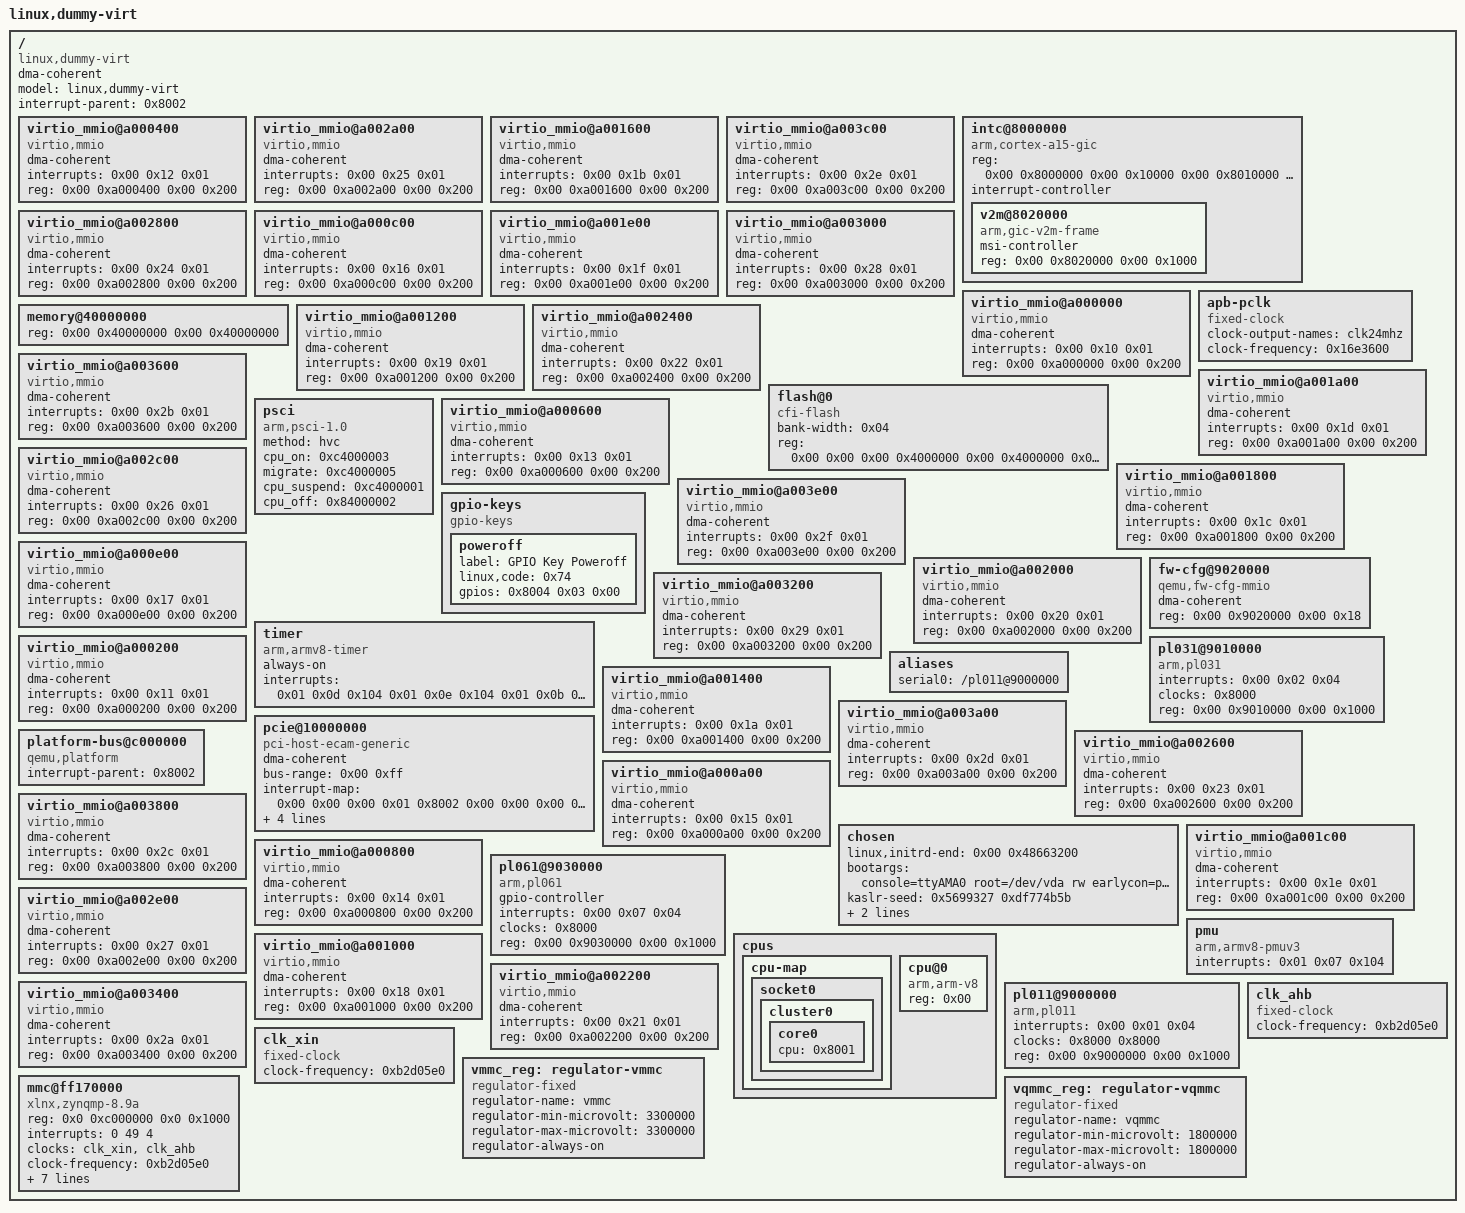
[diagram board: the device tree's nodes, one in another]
/dts-v1/;

/ {
	#address-cells = <0x02>;
	dma-coherent;
	model = "linux,dummy-virt";
	#size-cells = <0x02>;
	interrupt-parent = <0x8002>;
	compatible = "linux,dummy-virt";

	virtio_mmio@a000400 {
		dma-coherent;
		interrupts = <0x00 0x12 0x01>;
		compatible = "virtio,mmio";
		reg = <0x00 0xa000400 0x00 0x200>;
	};

	virtio_mmio@a002a00 {
		dma-coherent;
		interrupts = <0x00 0x25 0x01>;
		compatible = "virtio,mmio";
		reg = <0x00 0xa002a00 0x00 0x200>;
	};

	virtio_mmio@a001600 {
		dma-coherent;
		interrupts = <0x00 0x1b 0x01>;
		compatible = "virtio,mmio";
		reg = <0x00 0xa001600 0x00 0x200>;
	};

	virtio_mmio@a003c00 {
		dma-coherent;
		interrupts = <0x00 0x2e 0x01>;
		compatible = "virtio,mmio";
		reg = <0x00 0xa003c00 0x00 0x200>;
	};

	intc@8000000 {
		#address-cells = <0x02>;
		#size-cells = <0x02>;
		compatible = "arm,cortex-a15-gic";
		ranges;
		#interrupt-cells = <0x03>;
		reg = <0x00 0x8000000 0x00 0x10000 0x00 0x8010000 0x00 0x10000>;
		phandle = <0x8002>;
		interrupt-controller;

		v2m@8020000 {
			msi-controller;
			compatible = "arm,gic-v2m-frame";
			reg = <0x00 0x8020000 0x00 0x1000>;
			phandle = <0x8003>;
		};
	};

	virtio_mmio@a002800 {
		dma-coherent;
		interrupts = <0x00 0x24 0x01>;
		compatible = "virtio,mmio";
		reg = <0x00 0xa002800 0x00 0x200>;
	};

	virtio_mmio@a000c00 {
		dma-coherent;
		interrupts = <0x00 0x16 0x01>;
		compatible = "virtio,mmio";
		reg = <0x00 0xa000c00 0x00 0x200>;
	};

	virtio_mmio@a001e00 {
		dma-coherent;
		interrupts = <0x00 0x1f 0x01>;
		compatible = "virtio,mmio";
		reg = <0x00 0xa001e00 0x00 0x200>;
	};

	virtio_mmio@a003000 {
		dma-coherent;
		interrupts = <0x00 0x28 0x01>;
		compatible = "virtio,mmio";
		reg = <0x00 0xa003000 0x00 0x200>;
	};
	
	virtio_mmio@a000000 {
		dma-coherent;
		interrupts = <0x00 0x10 0x01>;
		compatible = "virtio,mmio";
		reg = <0x00 0xa000000 0x00 0x200>;
	};

	memory@40000000 {
		device_type = "memory";
		reg = <0x00 0x40000000 0x00 0x40000000>;
	};

	apb-pclk {
		clock-output-names = "clk24mhz";
		#clock-cells = <0x00>;
		clock-frequency = <0x16e3600>;
		compatible = "fixed-clock";
		phandle = <0x8000>;
	};

	virtio_mmio@a001200 {
		dma-coherent;
		interrupts = <0x00 0x19 0x01>;
		compatible = "virtio,mmio";
		reg = <0x00 0xa001200 0x00 0x200>;
	};

	virtio_mmio@a002400 {
		dma-coherent;
		interrupts = <0x00 0x22 0x01>;
		compatible = "virtio,mmio";
		reg = <0x00 0xa002400 0x00 0x200>;
	};

	virtio_mmio@a003600 {
		dma-coherent;
		interrupts = <0x00 0x2b 0x01>;
		compatible = "virtio,mmio";
		reg = <0x00 0xa003600 0x00 0x200>;
	};

	virtio_mmio@a001a00 {
		dma-coherent;
		interrupts = <0x00 0x1d 0x01>;
		compatible = "virtio,mmio";
		reg = <0x00 0xa001a00 0x00 0x200>;
	};

	flash@0 {
		bank-width = <0x04>;
		compatible = "cfi-flash";
		reg = <0x00 0x00 0x00 0x4000000 0x00 0x4000000 0x00 0x4000000>;
	};

	psci {
		method = "hvc";
		compatible = "arm,psci-1.0", "arm,psci-0.2", "arm,psci";
		cpu_on = <0xc4000003>;
		migrate = <0xc4000005>;
		cpu_suspend = <0xc4000001>;
		cpu_off = <0x84000002>;
	};

	virtio_mmio@a000600 {
		dma-coherent;
		interrupts = <0x00 0x13 0x01>;
		compatible = "virtio,mmio";
		reg = <0x00 0xa000600 0x00 0x200>;
	};

	virtio_mmio@a002c00 {
		dma-coherent;
		interrupts = <0x00 0x26 0x01>;
		compatible = "virtio,mmio";
		reg = <0x00 0xa002c00 0x00 0x200>;
	};

	virtio_mmio@a001800 {
		dma-coherent;
		interrupts = <0x00 0x1c 0x01>;
		compatible = "virtio,mmio";
		reg = <0x00 0xa001800 0x00 0x200>;
	};

	virtio_mmio@a003e00 {
		dma-coherent;
		interrupts = <0x00 0x2f 0x01>;
		compatible = "virtio,mmio";
		reg = <0x00 0xa003e00 0x00 0x200>;
	};

	gpio-keys {
		compatible = "gpio-keys";

		poweroff {
			label = "GPIO Key Poweroff";
			linux,code = <0x74>;
			gpios = <0x8004 0x03 0x00>;
		};
	};

	virtio_mmio@a000e00 {
		dma-coherent;
		interrupts = <0x00 0x17 0x01>;
		compatible = "virtio,mmio";
		reg = <0x00 0xa000e00 0x00 0x200>;
	};

	virtio_mmio@a002000 {
		dma-coherent;
		interrupts = <0x00 0x20 0x01>;
		compatible = "virtio,mmio";
		reg = <0x00 0xa002000 0x00 0x200>;
	};

	fw-cfg@9020000 {
		dma-coherent;
		compatible = "qemu,fw-cfg-mmio";
		reg = <0x00 0x9020000 0x00 0x18>;
	};

	timer {
		always-on;
		interrupts = <0x01 0x0d 0x104 0x01 0x0e 0x104 0x01 0x0b 0x104 0x01 0x0a 0x104>;
		compatible = "arm,armv8-timer", "arm,armv7-timer";
	};

	virtio_mmio@a003200 {
		dma-coherent;
		interrupts = <0x00 0x29 0x01>;
		compatible = "virtio,mmio";
		reg = <0x00 0xa003200 0x00 0x200>;
	};

	virtio_mmio@a000200 {
		dma-coherent;
		interrupts = <0x00 0x11 0x01>;
		compatible = "virtio,mmio";
		reg = <0x00 0xa000200 0x00 0x200>;
	};

	pl031@9010000 {
		clock-names = "apb_pclk";
		interrupts = <0x00 0x02 0x04>;
		clocks = <0x8000>;
		compatible = "arm,pl031", "arm,primecell";
		reg = <0x00 0x9010000 0x00 0x1000>;
	};

	aliases {
		serial0 = "/pl011@9000000";
	};

	virtio_mmio@a001400 {
		dma-coherent;
		interrupts = <0x00 0x1a 0x01>;
		compatible = "virtio,mmio";
		reg = <0x00 0xa001400 0x00 0x200>;
	};

	pcie@10000000 {
		#address-cells = <0x03>;
		dma-coherent;
		bus-range = <0x00 0xff>;
		interrupt-map = <0x00 0x00 0x00 0x01 0x8002 0x00 0x00 0x00 0x03 0x04 0x00 0x00 0x00 0x02 0x8002 0x00 0x00 0x00 0x04 0x04 0x00 0x00 0x00 0x03 0x8002 0x00 0x00 0x00 0x05 0x04 0x00 0x00 0x00 0x04 0x8002 0x00 0x00 0x00 0x06 0x04 0x800 0x00 0x00 0x01 0x8002 0x00 0x00 0x00 0x04 0x04 0x800 0x00 0x00 0x02 0x8002 0x00 0x00 0x00 0x05 0x04 0x800 0x00 0x00 0x03 0x8002 0x00 0x00 0x00 0x06 0x04 0x800 0x00 0x00 0x04 0x8002 0x00 0x00 0x00 0x03 0x04 0x1000 0x00 0x00 0x01 0x8002 0x00 0x00 0x00 0x05 0x04 0x1000 0x00 0x00 0x02 0x8002 0x00 0x00 0x00 0x06 0x04 0x1000 0x00 0x00 0x03 0x8002 0x00 0x00 0x00 0x03 0x04 0x1000 0x00 0x00 0x04 0x8002 0x00 0x00 0x00 0x04 0x04 0x1800 0x00 0x00 0x01 0x8002 0x00 0x00 0x00 0x06 0x04 0x1800 0x00 0x00 0x02 0x8002 0x00 0x00 0x00 0x03 0x04 0x1800 0x00 0x00 0x03 0x8002 0x00 0x00 0x00 0x04 0x04 0x1800 0x00 0x00 0x04 0x8002 0x00 0x00 0x00 0x05 0x04>;
		#size-cells = <0x02>;
		device_type = "pci";
		interrupt-map-mask = <0x1800 0x00 0x00 0x07>;
		compatible = "pci-host-ecam-generic";
		ranges = <0x1000000 0x00 0x00 0x00 0x3eff0000 0x00 0x10000 0x2000000 0x00 0x10000000 0x00 0x10000000 0x00 0x2eff0000 0x3000000 0x80 0x00 0x80 0x00 0x80 0x00>;
		msi-map = <0x00 0x8003 0x00 0x10000>;
		#interrupt-cells = <0x01>;
		reg = <0x40 0x10000000 0x00 0x10000000>;
		linux,pci-domain = <0x00>;
	};

	virtio_mmio@a003a00 {
		dma-coherent;
		interrupts = <0x00 0x2d 0x01>;
		compatible = "virtio,mmio";
		reg = <0x00 0xa003a00 0x00 0x200>;
	};

	platform-bus@c000000 {
		#address-cells = <0x01>;
		#size-cells = <0x01>;
		interrupt-parent = <0x8002>;
		compatible = "qemu,platform", "simple-bus";
		ranges = <0x00 0x00 0xc000000 0x2000000>;
	};

	virtio_mmio@a002600 {
		dma-coherent;
		interrupts = <0x00 0x23 0x01>;
		compatible = "virtio,mmio";
		reg = <0x00 0xa002600 0x00 0x200>;
	};

	virtio_mmio@a000a00 {
		dma-coherent;
		interrupts = <0x00 0x15 0x01>;
		compatible = "virtio,mmio";
		reg = <0x00 0xa000a00 0x00 0x200>;
	};

	chosen {
		linux,initrd-end = <0x00 0x48663200>;
		bootargs = "console=ttyAMA0 root=/dev/vda rw earlycon=pl011,0x09000000";
		kaslr-seed = <0x5699327 0xdf774b5b>;
		linux,initrd-start = <0x00 0x48000000>;
		stdout-path = "/pl011@9000000";
	};

	virtio_mmio@a003800 {
		dma-coherent;
		interrupts = <0x00 0x2c 0x01>;
		compatible = "virtio,mmio";
		reg = <0x00 0xa003800 0x00 0x200>;
	};

	virtio_mmio@a001c00 {
		dma-coherent;
		interrupts = <0x00 0x1e 0x01>;
		compatible = "virtio,mmio";
		reg = <0x00 0xa001c00 0x00 0x200>;
	};

	virtio_mmio@a000800 {
		dma-coherent;
		interrupts = <0x00 0x14 0x01>;
		compatible = "virtio,mmio";
		reg = <0x00 0xa000800 0x00 0x200>;
	};

	pl061@9030000 {
		clock-names = "apb_pclk";
		gpio-controller;
		interrupts = <0x00 0x07 0x04>;
		clocks = <0x8000>;
		compatible = "arm,pl061", "arm,primecell";
		reg = <0x00 0x9030000 0x00 0x1000>;
		phandle = <0x8004>;
		#gpio-cells = <0x02>;
	};

	virtio_mmio@a002e00 {
		dma-coherent;
		interrupts = <0x00 0x27 0x01>;
		compatible = "virtio,mmio";
		reg = <0x00 0xa002e00 0x00 0x200>;
	};

	pmu {
		interrupts = <0x01 0x07 0x104>;
		compatible = "arm,armv8-pmuv3";
	};

	cpus {
		#address-cells = <0x01>;
		#size-cells = <0x00>;

		cpu-map {

			socket0 {

				cluster0 {

					core0 {
						cpu = <0x8001>;
					};
				};
			};
		};

		cpu@0 {
			device_type = "cpu";
			compatible = "arm,arm-v8";
			reg = <0x00>;
			phandle = <0x8001>;
		};
	};

	virtio_mmio@a001000 {
		dma-coherent;
		interrupts = <0x00 0x18 0x01>;
		compatible = "virtio,mmio";
		reg = <0x00 0xa001000 0x00 0x200>;
	};

	virtio_mmio@a002200 {
		dma-coherent;
		interrupts = <0x00 0x21 0x01>;
		compatible = "virtio,mmio";
		reg = <0x00 0xa002200 0x00 0x200>;
	};

	pl011@9000000 {
		clock-names = "uartclk", "apb_pclk";
		interrupts = <0x00 0x01 0x04>;
		clocks = <0x8000 0x8000>;
		compatible = "arm,pl011", "arm,primecell";
		reg = <0x00 0x9000000 0x00 0x1000>;
	};

	virtio_mmio@a003400 {
		dma-coherent;
		interrupts = <0x00 0x2a 0x01>;
		compatible = "virtio,mmio";
		reg = <0x00 0xa003400 0x00 0x200>;
	};
	
	clk_ahb: clk_ahb {
		compatible = "fixed-clock";
		#clock-cells = <0>;
		clock-frequency = <0xb2d05e0>;
	};

	clk_xin: clk_xin {
		compatible = "fixed-clock";
		#clock-cells = <0>;
		clock-frequency = <0xb2d05e0>;
	};

	vmmc_reg: regulator-vmmc {
		compatible = "regulator-fixed";
		regulator-name = "vmmc";
		regulator-min-microvolt = <3300000>;
		regulator-max-microvolt = <3300000>;
		regulator-always-on;
	};

	vqmmc_reg: regulator-vqmmc {
		compatible = "regulator-fixed";
		regulator-name = "vqmmc";
		regulator-min-microvolt = <1800000>;
		regulator-max-microvolt = <1800000>;
		regulator-always-on;
	};

	mmc@ff170000 {
		compatible = "xlnx,zynqmp-8.9a", "arasan,sdhci-8.9a";
		reg = <0x0 0xc000000 0x0 0x1000>; /* Address gotten from info mtree in QEMU */
		interrupts = <0 49 4>; /* Ensure the correct IRQ number is injected */
		status = "okay";
		clocks = <&clk_xin>, <&clk_ahb> ;
		clock-names = "clk_xin", "clk_ahb";
		clock-frequency = <0xb2d05e0>;
		assigned-clocks = <&clk_xin>, <&clk_ahb>;
    		assigned-clock-rates = <189000000>, <189000000>;
		vmmc-supply = <&vmmc_reg>;
		vqmmc-supply = <&vqmmc_reg>;
		voltage-ranges = <3300 3300>;
		no-1-8-v;
		disable-wp;
	};
};

